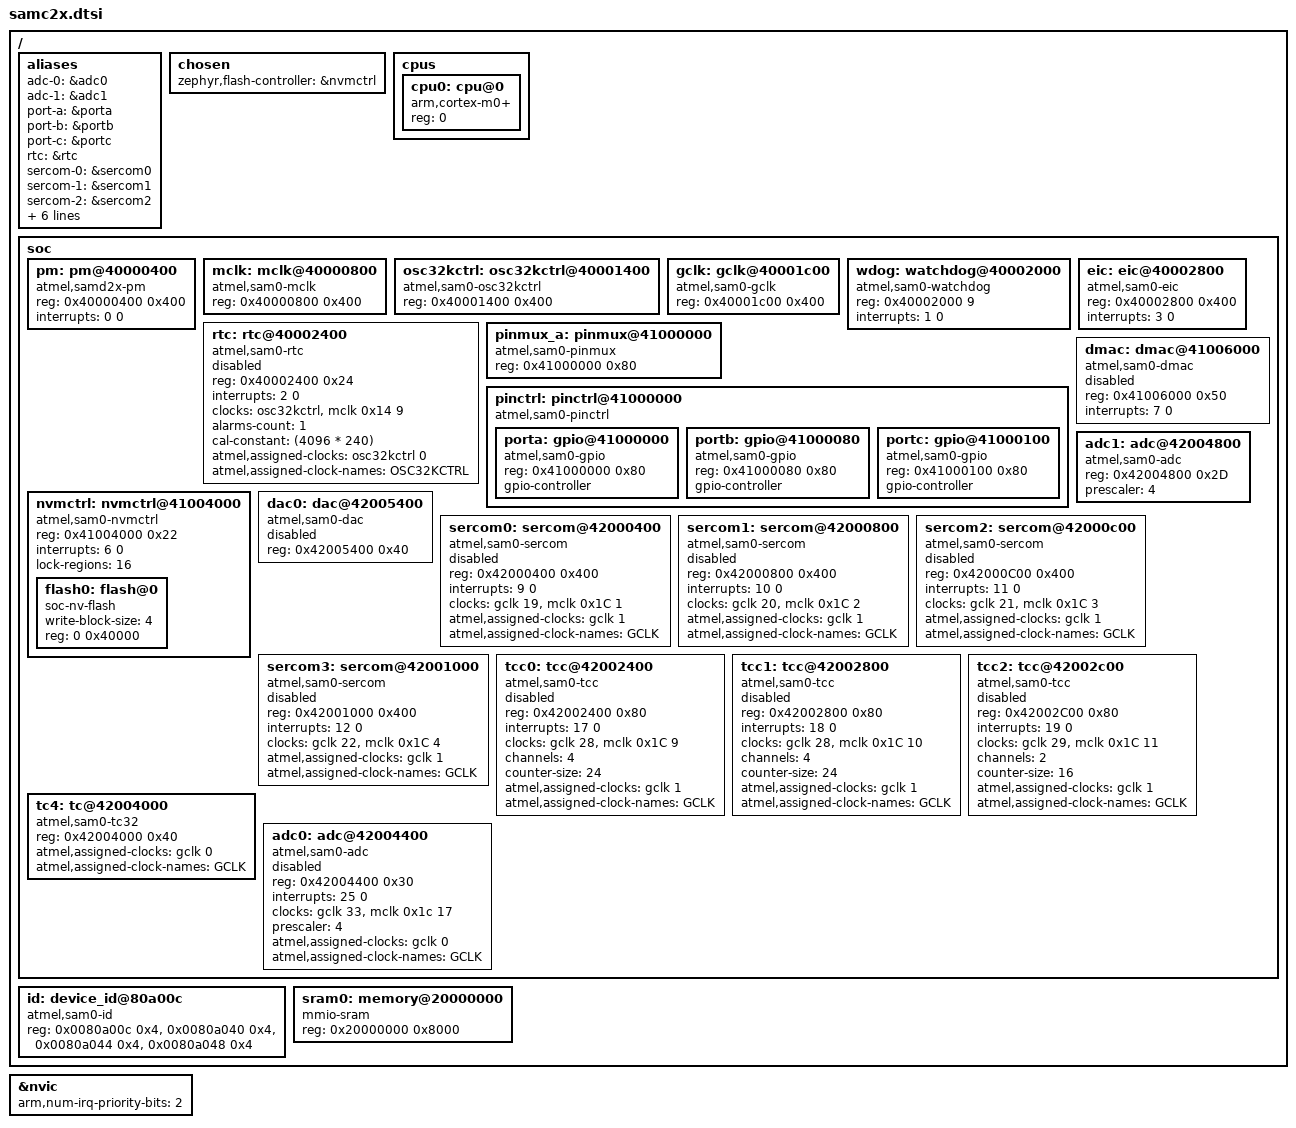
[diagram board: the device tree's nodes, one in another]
/*
 * Copyright (c) 2017 Google LLC.
 * Copyright (c) 2022 Kamil Serwus
 * Copyright (c) 2024-2025 Gerson Fernando Budke <nandojve@gmail.com>
 * Copyright (c) 2026 Microchip Technology Inc.
 *
 * SPDX-License-Identifier: Apache-2.0
 */

#include <mem.h>
#include <arm/armv6-m.dtsi>
#include <zephyr/dt-bindings/adc/adc.h>
#include <zephyr/dt-bindings/gpio/gpio.h>
#include <zephyr/dt-bindings/i2c/i2c.h>
#include <zephyr/dt-bindings/pwm/pwm.h>

/* @see Table 10-3. Interrupt Line Mapping, SAM C21 for interrupts number !!! */
/ {
	aliases {
		adc-0 = &adc0;
		adc-1 = &adc1;

		port-a = &porta;
		port-b = &portb;
		port-c = &portc;

		rtc = &rtc;

		sercom-0 = &sercom0;
		sercom-1 = &sercom1;
		sercom-2 = &sercom2;
		sercom-3 = &sercom3;

		tcc-0 = &tcc0;
		tcc-1 = &tcc1;
		tcc-2 = &tcc2;

		tc-4 = &tc4;
		watchdog0 = &wdog;
	};

	chosen {
		zephyr,flash-controller = &nvmctrl;
	};

	cpus {
		#address-cells = <1>;
		#size-cells = <0>;

		cpu0: cpu@0 {
			compatible = "arm,cortex-m0+";
			reg = <0>;

			device_type = "cpu";
		};
	};

	soc {
		pm: pm@40000400 {
			compatible = "atmel,samd2x-pm";
			reg = <0x40000400 0x400>;
			interrupts = <0 0>;
			#clock-cells = <2>;
		};

		mclk: mclk@40000800 {
			compatible = "atmel,sam0-mclk";
			reg = <0x40000800 0x400>;

			#clock-cells = <2>;
		};

		osc32kctrl: osc32kctrl@40001400 {
			compatible = "atmel,sam0-osc32kctrl";
			reg = <0x40001400 0x400>;
			#clock-cells = <0>;
			#atmel,assigned-clock-cells = <1>;
		};

		gclk: gclk@40001c00 {
			compatible = "atmel,sam0-gclk";
			reg = <0x40001c00 0x400>;

			#clock-cells = <1>;
			#atmel,assigned-clock-cells = <1>;
		};

		wdog: watchdog@40002000 {
			compatible = "atmel,sam0-watchdog";
			reg = <0x40002000 9>;
			interrupts = <1 0>;
		};

		rtc: rtc@40002400 {
			compatible = "atmel,sam0-rtc";
			reg = <0x40002400 0x24>;
			interrupts = <2 0>;
			clocks = <&osc32kctrl>, <&mclk 0x14 9>;
			clock-names = "OSC32KCTRL", "MCLK";

			alarms-count = <1>;
			cal-constant = <(4096 * 240)>;
			atmel,assigned-clocks = <&osc32kctrl 0>;
			atmel,assigned-clock-names = "OSC32KCTRL";
			status = "disabled";
		};

		eic: eic@40002800 {
			compatible = "atmel,sam0-eic";
			reg = <0x40002800 0x400>;
			interrupts = <3 0>;
		};

		pinmux_a: pinmux@41000000 {
			compatible = "atmel,sam0-pinmux";
			reg = <0x41000000 0x80>;
		};

		pinctrl: pinctrl@41000000 {
			compatible = "atmel,sam0-pinctrl";
			ranges = <0x41000000 0x41000000 0x180>;

			#address-cells = <1>;
			#size-cells = <1>;

			porta: gpio@41000000 {
				compatible = "atmel,sam0-gpio";
				reg = <0x41000000 0x80>;
				#gpio-cells = <2>;

				gpio-controller;

				#atmel,pin-cells = <2>;
			};

			portb: gpio@41000080 {
				compatible = "atmel,sam0-gpio";
				reg = <0x41000080 0x80>;
				#gpio-cells = <2>;

				gpio-controller;

				#atmel,pin-cells = <2>;
			};

			portc: gpio@41000100 {
				compatible = "atmel,sam0-gpio";
				reg = <0x41000100 0x80>;
				#gpio-cells = <2>;

				gpio-controller;

				#atmel,pin-cells = <2>;
			};
		};

		nvmctrl: nvmctrl@41004000 {
			compatible = "atmel,sam0-nvmctrl";
			reg = <0x41004000 0x22>;
			ranges;
			interrupts = <6 0>;
			#address-cells = <1>;
			#size-cells = <1>;

			lock-regions = <16>;

			flash0: flash@0 {
				compatible = "soc-nv-flash";
				ranges;

				write-block-size = <4>;
				reg = <0 0x40000>;
				#address-cells = <1>;
				#size-cells = <1>;
			};
		};

		dmac: dmac@41006000 {
			compatible = "atmel,sam0-dmac";
			reg = <0x41006000 0x50>;
			interrupts = <7 0>;

			#dma-cells = <2>;
			status = "disabled";
		};

		adc1: adc@42004800 {
			compatible = "atmel,sam0-adc";
			reg = <0x42004800 0x2D>;

			prescaler = <4>;
			#io-channel-cells = <1>;
		};

		dac0: dac@42005400 {
			compatible = "atmel,sam0-dac";
			status = "disabled";
			reg = <0x42005400 0x40>;
			#io-channel-cells = <0>;
		};

		sercom0: sercom@42000400 {
			compatible = "atmel,sam0-sercom";
			reg = <0x42000400 0x400>;
			interrupts = <9 0>;
			clocks = <&gclk 19>, <&mclk 0x1C 1>;
			clock-names = "GCLK", "MCLK";
			atmel,assigned-clocks = <&gclk 1>;      /* #CUSTOM@NDRS : Use GCLK1 instead of GCLK0 */
			atmel,assigned-clock-names = "GCLK";
			status = "disabled";
		};

		sercom1: sercom@42000800 {
			compatible = "atmel,sam0-sercom";
			reg = <0x42000800 0x400>;
			interrupts = <10 0>;
			clocks = <&gclk 20>, <&mclk 0x1C 2>;
			clock-names = "GCLK", "MCLK";
			atmel,assigned-clocks = <&gclk 1>;      /* #CUSTOM@NDRS : Use GCLK1 instead of GCLK0 */
			atmel,assigned-clock-names = "GCLK";
			status = "disabled";
		};

		sercom2: sercom@42000c00 {
			compatible = "atmel,sam0-sercom";
			reg = <0x42000C00 0x400>;
			interrupts = <11 0>;
			clocks = <&gclk 21>, <&mclk 0x1C 3>;
			clock-names = "GCLK", "MCLK";
			atmel,assigned-clocks = <&gclk 1>;      /* #CUSTOM@NDRS : Use GCLK1 instead of GCLK0 */
			atmel,assigned-clock-names = "GCLK";
			status = "disabled";
		};

		sercom3: sercom@42001000 {
			compatible = "atmel,sam0-sercom";
			reg = <0x42001000 0x400>;
			interrupts = <12 0>;
			clocks = <&gclk 22>, <&mclk 0x1C 4>;
			clock-names = "GCLK", "MCLK";
			atmel,assigned-clocks = <&gclk 1>;      /* #CUSTOM@NDRS : Use GCLK1 instead of GCLK0 */
			atmel,assigned-clock-names = "GCLK";
			status = "disabled";
		};

		tcc0: tcc@42002400 {
			compatible = "atmel,sam0-tcc";
			reg = <0x42002400 0x80>;
			interrupts = <17 0>;
			clocks = <&gclk 28>, <&mclk 0x1C 9>;
			clock-names = "GCLK", "MCLK";

			channels = <4>;
			counter-size = <24>;
			atmel,assigned-clocks = <&gclk 1>;      /* #CUSTOM@NDRS : Use GCLK1 instead of GCLK0 */
			atmel,assigned-clock-names = "GCLK";
			status = "disabled";
		};

		tcc1: tcc@42002800 {
			compatible = "atmel,sam0-tcc";
			reg = <0x42002800 0x80>;
			interrupts = <18 0>;
			clocks = <&gclk 28>, <&mclk 0x1C 10>;
			clock-names = "GCLK", "MCLK";

			channels = <4>;
			counter-size = <24>;
			atmel,assigned-clocks = <&gclk 1>;      /* #CUSTOM@NDRS : Use GCLK1 instead of GCLK0 */
			atmel,assigned-clock-names = "GCLK";
			status = "disabled";
		};

		tcc2: tcc@42002c00 {
			compatible = "atmel,sam0-tcc";
			reg = <0x42002C00 0x80>;
			interrupts = <19 0>;
			clocks = <&gclk 29>, <&mclk 0x1C 11>;
			clock-names = "GCLK", "MCLK";

			channels = <2>;
			counter-size = <16>;
			atmel,assigned-clocks = <&gclk 1>;      /* #CUSTOM@NDRS : Use GCLK1 instead of GCLK0 */
			atmel,assigned-clock-names = "GCLK";
			status = "disabled";
		};

		tc4: tc@42004000 {
			compatible = "atmel,sam0-tc32";
			reg = <0x42004000 0x40>;

			atmel,assigned-clocks = <&gclk 0>;
			atmel,assigned-clock-names = "GCLK";
		};

		adc0: adc@42004400 {
			compatible = "atmel,sam0-adc";
			reg = <0x42004400 0x30>;
			interrupts = <25 0>;
			interrupt-names = "resrdy";
			clocks = <&gclk 33>, <&mclk 0x1c 17>;
			clock-names = "GCLK", "MCLK";

			#io-channel-cells = <1>;

			prescaler = <4>;
			atmel,assigned-clocks = <&gclk 0>;
			atmel,assigned-clock-names = "GCLK";
			status = "disabled";
		};
	};

	id: device_id@80a00c {
		compatible = "atmel,sam0-id";
		reg = <0x0080a00c 0x4>,
		      <0x0080a040 0x4>,
		      <0x0080a044 0x4>,
		      <0x0080a048 0x4>;
	};

	sram0: memory@20000000 {
		compatible = "mmio-sram";
		reg = <0x20000000 0x8000>;
	};
};

&nvic {
	arm,num-irq-priority-bits = <2>;
};
